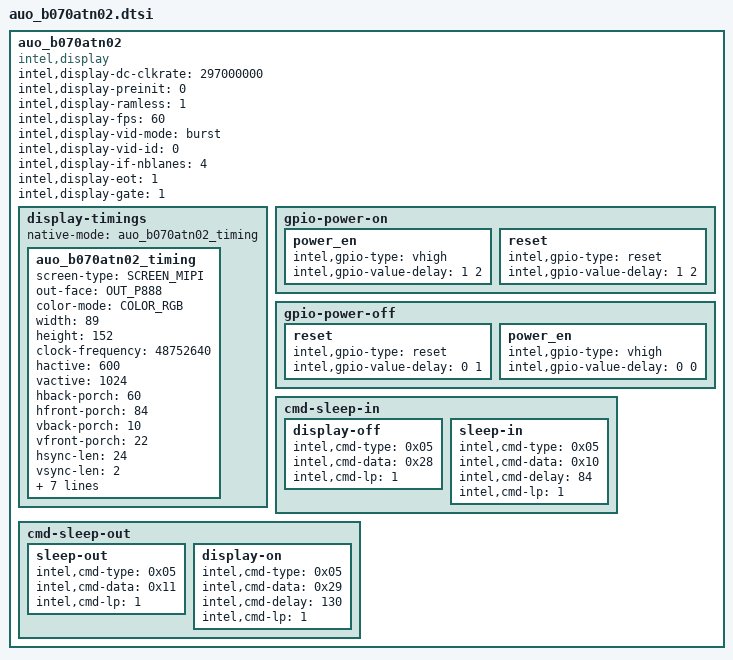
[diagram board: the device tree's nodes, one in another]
/*
 * definition at "include/dt-bindings/sofiafb/sofia_fb.h"
 */


auo_b070atn02 {
	compatible = "intel,display";
	intel,display-dc-clkrate = <297000000>;
	intel,display-preinit = <0>;
	intel,display-ramless = <1>;
	intel,display-fps = <60>;
	intel,display-vid-mode = "burst";
	intel,display-vid-id = <0>;
	intel,display-if-nblanes = <4>;
	intel,display-eot = <1>;
	intel,display-gate = <1>;

	display-timings {
		native-mode = <&auo_b070atn02_timing>;
		auo_b070atn02_timing: auo_b070atn02_timing {
			screen-type = <SCREEN_MIPI>;
			out-face    = <OUT_P888>;
			color-mode = <COLOR_RGB>;
			width = <89>;
			height = <152>;
			clock-frequency = <48752640>;
			hactive = <600>;
			vactive = <1024>;
			hback-porch = <60>;
			hfront-porch = <84>;
			vback-porch = <10>;
			vfront-porch = <22>;
			hsync-len = <24>;
			vsync-len = <2>;
			hsync-active = <0>;
			vsync-active = <0>;
			de-active = <0>;
			pixelclk-active = <0>;
			swap-rb = <0>;
			swap-rg = <0>;
			swap-gb = <0>;
		};
	};

	gpio-power-on {
		power_en {
			intel,gpio-type = "vhigh";
			intel,gpio-value-delay = <1 2>;
	};
		reset {
			intel,gpio-type = "reset";
			intel,gpio-value-delay = <1 2>;
		};
	};

	gpio-power-off {
		reset {
			intel,gpio-type = "reset";
			intel,gpio-value-delay = <0 1>;
		};
		power_en {
			intel,gpio-type = "vhigh";
			intel,gpio-value-delay = <0 0>;
		};
	};

	cmd-sleep-in {
		display-off{
			intel,cmd-type = <0x05>;
			intel,cmd-data = <0x28>;
			intel,cmd-lp = <1>;
		};
		sleep-in{
			intel,cmd-type = <0x05>;
			intel,cmd-data = <0x10>;
			intel,cmd-delay = <84>;
			intel,cmd-lp = <1>;
		};
	};

	cmd-sleep-out {
		sleep-out{
			intel,cmd-type = <0x05>;
			intel,cmd-data = <0x11>;
			intel,cmd-lp = <1>;
		};
		display-on{
			intel,cmd-type = <0x05>;
			intel,cmd-data = <0x29>;
			intel,cmd-delay = <130>;
			intel,cmd-lp = <1>;
		};
	};
};

